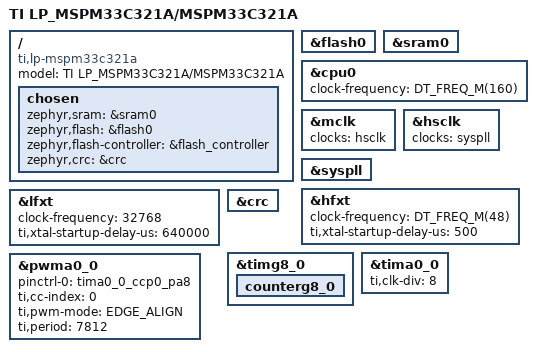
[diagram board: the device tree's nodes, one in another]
/*
 * Copyright (c) 2026 Texas Instruments
 * SPDX-License-Identifier: Apache-2.0
 */

/dts-v1/;

#include <ti/mspm33c/mspm33c321a.dtsi>
#include <ti/mspm33c/mspm33c321a-pinctrl.dtsi>
#include <zephyr/dt-bindings/pwm/pwm.h>

/ {
	compatible = "ti,lp-mspm33c321a";
	model = "TI LP_MSPM33C321A/MSPM33C321A";

	chosen {
		zephyr,sram = &sram0;
		zephyr,flash = &flash0;
		zephyr,flash-controller = &flash_controller;
		zephyr,crc = &crc;
	};
};

&flash0 {
	status = "okay";
};

&sram0 {
	status = "okay";
};

&cpu0 {
	clock-frequency = <DT_FREQ_M(160)>;
};

&mclk {
	clocks = <&hsclk>;
};

&hsclk {
	clocks = <&syspll>;
	status = "okay";
};

&syspll {
	status = "okay";
};

&hfxt {
	clock-frequency = <DT_FREQ_M(48)>;
	ti,xtal-startup-delay-us = <500>;
};

&lfxt {
	clock-frequency = <32768>;
	ti,xtal-startup-delay-us = <640000>;
};

&crc {
	status = "okay";
};

&timg8_0 {
	status = "okay";

	counterg8_0: counterg8_0 {
		status = "okay";
	};
};

&tima0_0 {
	ti,clk-div = <8>;
};

&pwma0_0 {
	pinctrl-0 = <&tima0_0_ccp0_pa8>;
	pinctrl-names = "default";
	ti,cc-index = <0>;
	ti,pwm-mode = "EDGE_ALIGN";
	ti,period = <7812>; /* ~100 ms at 78,125 Hz */
	status = "okay";
};
